# pse84 register map
Vendor: Cypress Semiconductor; Series: PSE84; File version: 1.0
CPU: CM33 r0p1, little endian, MPU, FPU, VTOR, 3 interrupt priority bits
Registers are 32-bit, read-write, reset 0x0 unless marked. A register's access mark holds for its fields unless they carry their own. Offsets are from the block's base; [hi:lo] are bit positions; lines under a group give offsets from that group; {n}, {i} and the like mark numbered series; 'fields as' and 'values as' point back to an identical list; <NAME> marks a mode.

## SRSS (part 2 of 3) — SRSS Core Registers
Base 0x42400000
0x1394 CLK_WCO_STATUS ro — WCO Status Register
  [2] WCO_OK — Indicates that output has transitioned.
0x1400 CSV_HF group — Clock Supervisor (CSV) registers for Root clocks
  {0x0+0x10*j} CSV[{j}] (j=0..13) group — Active domain Clock Supervisor (CSV) registers
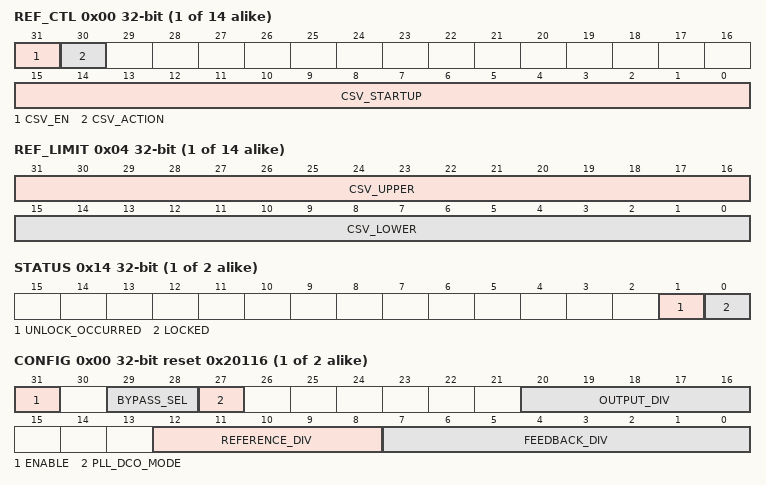
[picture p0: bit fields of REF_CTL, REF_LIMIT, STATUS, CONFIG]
    0x00 REF_CTL — Clock Supervision Reference Control
      [31] CSV_EN — Enables clock supervision, both frequency and loss. CSV in Active domain: Clock supervision is reset during DeepSleep and Hibernate modes. When enabled it begins operating automatically after a DeepSleep wakeup, but it must be reconfigured after Hibernate wakeup. CSV in DeepSleep domain: Clock supervision is reset during Hibernate mode. It must be reconfigured after Hibernate wakeup. A CSV error detection is reported to the Fault structure, or instead it can generate a power reset.
      [30] CSV_ACTION — Specifies the action taken when an anomaly is detected on the monitored clock. CSV in DeepSleep domain always do a Fault report (which also wakes up the system).
        0=FAULT (Generate a fault); 1=RESET (Cause a power reset. This should only be used for clk_hf0.)
      [15:0] CSV_STARTUP — Startup delay time -1 (in reference clock cycles), after enable or DeepSleep wakeup, from reference clock start to monitored clock start. At a minimum (both clocks running): STARTUP >= (PERIOD +3) * FREQ_RATIO - UPPER, with FREQ_RATIO = (Reference frequency / Monitored frequency) On top of that the actual clock startup delay and the margin for accuracy of both clocks must be added.
    0x04 REF_LIMIT — Clock Supervision Reference Limits
      [31:16] CSV_UPPER — Cycle time upper limit. Set the upper limit -1, in reference clock cycles, before (or same time) the next monitored clock event must happen. If a monitored clock event does not happen before this limit is reached, or does not happen at all (clock loss), a CSV error is detected.
      [15:0] CSV_LOWER — Cycle time lower limit. Set the lower limit -1, in reference clock cycles, before the next monitored clock event is allowed to happen. If a monitored clock event happens before this limit is reached a CSV error is detected. LOWER must be at least 1 less than UPPER. In case the clocks are asynchronous LOWER must be at least 3 less than UPPER.
    0x08 MON_CTL — Clock Supervision Monitor Control
      [15:0] CSV_PERIOD — Period time. Set the Period -1, in monitored clock cycles, before the next monitored clock event happens. PERIOD <= (UPPER+1) / FREQ_RATIO -1, with FREQ_RATIO = (Reference frequency / Monitored frequency) In case the clocks are asynchronous: PERIOD <= UPPER / FREQ_RATIO -1 Additionally margin must be added for accuracy of both clocks.
0x1500 CSV_REF_SEL reset 0x4 — Select CSV Reference clock for Active domain
  [2:0] REF_MUX — Selects a source for clock clk_ref_hf. Note that not all products support all clock sources. Selecting a clock source that is not supported will result in undefined behavior. It takes four cycles of the originally selected clock to switch away from it. Do not disable the original clock during this time.
    0=IMO (IMO - Internal R/C Oscillator (product specific)); 1=EXTCLK (EXTCLK - External Clock Pin); 2=ECO (ECO - External-Crystal Oscillator); 3=ALTHF0 (ALTHF0 - Alternate High-Frequency clock input (product-specific clock)); 4=IHO (IHO - Internal High-speed Oscillator); 5=ALTHF1 (ALTHF1 - Alternate High-Frequency clock input (product-specific clock))
0x1510 CSV_REF group — CSV registers for the CSV Reference clock
  0x00 CSV group — Active domain Clock Supervisor (CSV) registers for CSV Reference clock
    0x00 REF_CTL — Clock Supervision Reference Control
      fields as CSV_HF.CSV[0].REF_CTL
    0x04 REF_LIMIT — Clock Supervision Reference Limits
      fields as CSV_HF.CSV[0].REF_LIMIT
    0x08 MON_CTL — Clock Supervision Monitor Control
      fields as CSV_HF.CSV[0].MON_CTL
0x1520 CSV_LF_REF_SEL — Select CSV Reference clock for LF clock
  [1:0] LF_REF_MUX — Selects a source for clock clk_ref_lf. Note that not all products support all clock sources. Selecting a clock source that is not supported will result in undefined behavior. It takes four cycles of the originally selected clock to switch away from it. Do not disable the original clock during this time. Same clcok sources are also souce for clk_lf. Do not select the same clock.
    0=PILO (Precision internal low-speed oscillator, available in Active, DeepSleep, and Hibernate. (Product Specific)); 1=ILO (Internal Low frequency Oscillator, available in Active, DeepSleep, and Hibernate. (Product Specific)); 2=WCO (Watch-crystal oscillator input, available in Active, DeepSleep, and Hibernate. (Product Specific)); 3=TIMERCLK (Timer clock. Divided clock from IHO set to 1MHz. Available only during Active mode. If this clock is selected as reference, CSV will be disabled by hardware when entering lower power modes (DPSLP) and re-enabled back in Active.)
0x1530 CSV_LF group — CSV registers for LF clock
  0x00 CSV group — LF clock Clock Supervisor registers
    0x00 REF_CTL — Clock Supervision Reference Control
      [31] CSV_EN — Enables clock supervision, both frequency and loss. CSV in Active domain: Clock supervision is reset during DeepSleep and Hibernate modes. When enabled it begins operating automatically after a DeepSleep wakeup, but it must be reconfigured after Hibernate wakeup. CSV in DeepSleep domain: Clock supervision is reset during Hibernate mode. It must be reconfigured after Hibernate wakeup. CSV in Backup domain: Clock supervision operates during Hibernate mode, can be configured to wake from Hibernate, and continues operating during reboot. A CSV error detection is reported to the Fault structure.
      [7:0] CSV_STARTUP — Startup delay time -1 (in reference clock cycles), after enable, from reference clock start to monitored clock start. At a minimum (both clocks running): STARTUP >= (PERIOD +3) * FREQ_RATIO - UPPER, with FREQ_RATIO = (Reference frequency / Monitored frequency) On top of that the actual clock startup delay and the margin for accuracy of both clocks must be added.
    0x04 REF_LIMIT — Clock Supervision Reference Limits
      [23:16] CSV_UPPER — Cycle time upper limit. Set the upper limit -1, in reference clock cycles, before (or same time) the next monitored clock event must happen. If a monitored clock event does not happen before this limit is reached, or does not happen at all (clock loss), a CSV error is detected.
      [7:0] CSV_LOWER — Cycle time lower limit. Set the lower limit -1, in reference clock cycles, before the next monitored clock event is allowed to happen. If a monitored clock event happens before this limit is reached a CSV error is detected. LOWER must be at least 1 less than UPPER. In case the clocks are asynchronous LOWER must be at least 3 less than UPPER.
    0x08 MON_CTL — Clock Supervision Monitor Control
      [7:0] CSV_PERIOD — Period time. Set the Period -1, in monitored clock cycles, before the next monitored clock event happens. PERIOD <= (UPPER+1) / FREQ_RATIO -1, with FREQ_RATIO = (Reference frequency / Monitored frequency) In case the clocks are asynchronous: PERIOD <= UPPER / FREQ_RATIO -1 Additionally margin must be added for accuracy of both clocks.
0x1540 CSV_PILO_REF_SEL — Select CSV Reference clock for PILO clock
  [1:0] PILO_REF_MUX — Selects a source for clock clk_ref_pilo. Note that not all products support all clock sources. Selecting a clock source that is not supported will result in undefined behavior. It takes four cycles of the originally selected clock to switch away from it. Do not disable the original clock during this time. PILO is a source for clk_lf. Do not select LF when LF clock is using PILO.
    0=LFCLK (Root of the low-speed clock tree (LFCLK)); 1=ILO (Internal Low frequency Oscillator, available in Active, DeepSleep, and Hibernate. (Product Specific)); 2=WCO (Watch-crystal oscillator input, available in Active, DeepSleep, and Hibernate. (Product Specific)); 3=TIMERCLK (Timer clock. Divided clock from IHO set to 1MHz. Available only during Active mode. If this clock is selected as reference, CSV will be disabled by hardware when entering lower power modes (DPSLP) and re-enabled back in Active.)
0x1550 CSV_PILO group — CSV registers for PILO clock
  0x00 CSV group — HVILO clock DeepSleep domain Clock Supervisor registers
    0x00 REF_CTL — Clock Supervision Reference Control
      fields as CSV_LF.CSV.REF_CTL
    0x04 REF_LIMIT — Clock Supervision Reference Limits
      fields as CSV_LF.CSV.REF_LIMIT
    0x08 MON_CTL — Clock Supervision Monitor Control
      fields as CSV_LF.CSV.MON_CTL
{0x1600+0x20*i} CLK_DPLL_LP[{i}] (i=0..1) group — DPLL LP Configuration Register
  0x00 CONFIG reset 0x20116 — DPLL_LP Configuration Register
    [31] ENABLE — Master enable for PLL. Setup FEEDBACK_DIV, REFERENCE_DIV, and OUTPUT_DIV at least one cycle before setting ENABLE=1. fOUT = (FEEDBACK_DIV + FRAC_EN*FRAC_DIV/2^24) * (fREF / REFERENCE_DIV) / (OUTPUT_DIV) 0: Block is disabled. When the PLL disables, hardware controls the bypass mux as described in BYPASS_SEL, before disabling the PLL circuit. 1: Block is enabled
    [29:28] BYPASS_SEL — Bypass mux located just after PLL output. This selection is glitch-free and can be changed while the PLL is running. When changing BYPASS_SEL, do not turn off the reference clock or PLL clock for five cycles (whichever is slower).
      0=AUTO (Automatic using lock indicator. When unlocked, automatically selects PLL reference input (bypass mode). When locked, automatically selects PLL output. If ENABLE=0, automatically selects PLL reference input.); 1=LOCKED_OR_NOTHING (Similar to AUTO, except the clock is gated off when unlocked. This is compatible with clock supervision, because the supervisors allow no clock during startup (until a timeout occurs), and the clock targets the proper frequency whenever it is running. If ENABLE=0, no clock is output.); 2=PLL_BYPASS (Select PLL reference input (bypass mode). Ignores lock indicator); 3=PLL_OUT (Select PLL output. Ignores lock indicator. If ENABLE=0, no clock is output.)
    [27] PLL_DCO_MODE — dco_mode='0' DCO freq 160-310MHz , '1' - DCO freq 310-480MHz
    [20:16] OUTPUT_DIV — Control bits for Output divider. Set the divide value before enabling the PLL, and do not change it while PLL is enabled. 0: illegal (undefined behavior) 1: divide by 1. Suitable for direct usage as HFCLK source. 2: divide by 2. Suitable for direct usage as HFCLK source. ... 16: divide by 16. Suitable for direct usage as HFCLK source. >16: illegal (undefined behavior)
    [12:8] REFERENCE_DIV — Control bits for reference divider. Set the divide value before enabling the PLL, and do not change it while PLL is enabled. 0: illegal (undefined behavior) 1: divide by 1 ... 16: divide by 16 others: illegal (undefined behavior) When using fractional mode, the jitter specs are met over the restricted range of 1 to 4, inclusive.
    [7:0] FEEDBACK_DIV — Control bits for feedback divider. Set the divide value before enabling the PLL, and do not change it while PLL is enabled. 0-15: illegal (undefined behavior) 16: divide by 16 ... 200: divide by 200 >200: illegal (undefined behavior) When using fractional mode, the jitter specs are met over the restricted range of 27 to 47, inclusive.
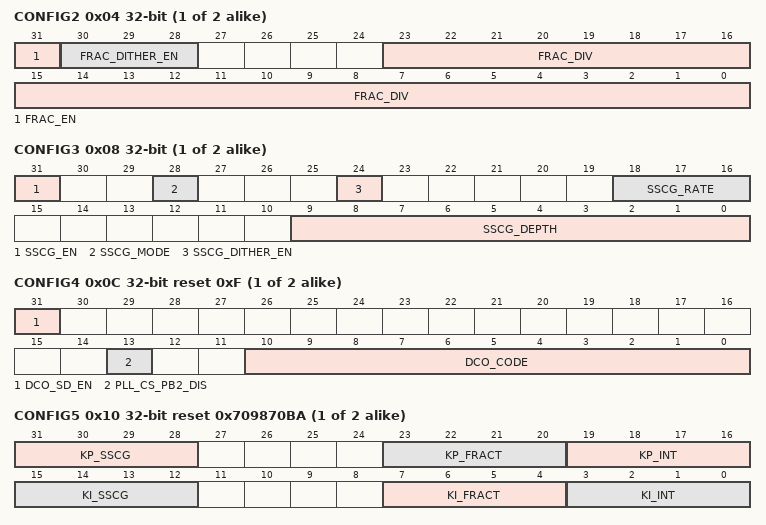
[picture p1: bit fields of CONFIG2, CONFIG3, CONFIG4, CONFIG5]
  0x04 CONFIG2 — DPLL_LP Configuration Register 2
    [31] FRAC_EN — Enables fractional division mode. When using fractional division mode, see CLK_PLL400M_CONFIG.LOCK_DELAY for an additional configuration requirement.
    [30:28] FRAC_DITHER_EN
    [23:0] FRAC_DIV — Control bits for fractional divider. This value is interpreted as a fraction of the PFD frequency, i.e. fPFD * (FRAC_DIV/2^24). This field can be dynamically updated within the 1000ppm control limit. It takes up to 115 AHB cycles to transfer the setting to the PLL, and writes that occur faster may be silently ignored and require the application to write again after the previous update has finished. Reading the register returns the accepted value. The PLL will start targeting the new value, but it may take significant time (milliseconds) to stabilize at the new average value. Do not change the FRAC_DIV setting while the PLL is initially locking.
  0x08 CONFIG3 — DPLL_LP Configuration Register 3
    [31] SSCG_EN — Enables spreading mode. When using spreading, see CLK_PLL400M_CONFIG.LOCK_DELAY for an additional configuration requirement.
    [28] SSCG_MODE
    [24] SSCG_DITHER_EN
    [18:16] SSCG_RATE
    [9:0] SSCG_DEPTH
  0x0C CONFIG4 reset 0xF — DPLL_LP Configuration Register 4
    [31] DCO_SD_EN — Enable the DCO sigma-delta modulator to reduce sideband frequency spurs caused by periodicity of DCO_CODE LSB changes. Note that enabling this introduces additional jitter which may exceed the timing closure limits near the maximum frequency. 0: disable sigma-delta modulator. 1: enable sigma-delta modulator. User must ensure the frequency remains with timing closure (consult Cypress).
    [13] PLL_CS_PB2_DIS — disable internal bias
    [10:0] DCO_CODE — Initial DCO code. It is recommended to leave this at the default setting.
  0x10 CONFIG5 reset 0x709870BA — DPLL_LP Configuration Register 5
    [31:28] KP_SSCG — Gain of P/I loop filter proportional path for SSCG operation. Gain coefficient is 2^KP, eg. 0=>1, 15=>32768.
    [23:20] KP_FRACT — Gain of P/I loop filter proportional path for FRACT operation. Gain coefficient is 2^KP, eg. 0=>1, 15=>32768.
    [19:16] KP_INT — Gain of P/I loop filter integrator path for INT operation. Gain coefficient is 2^KP, eg. 0=>1, 15=>32768.
    [15:12] KI_SSCG — Gain of P/I loop filter proportional path for SSCG operation. Gain coefficient is 2^KI, eg. 0=>1, 15=>32768.
    [7:4] KI_FRACT — Gain of P/I loop filter proportional path for FRACT operation. Gain coefficient is 2^KI, eg. 0=>1, 15=>32768.
    [3:0] KI_INT — Gain of P/I loop filter integrator path for INT operation. Gain coefficient is 2^KI, eg. 0=>1, 15=>32768.
  0x14 STATUS — DPLL_LP Status Register
    [1] UNLOCK_OCCURRED — This bit sets whenever the PLL Lock bit goes low, and stays set until cleared by firmware.
    [0] LOCKED ro — PLL Lock Indicator
0x1800 CLK_DPLL_HP group — DPLL HP Configuration Register
  0x00 CONFIG reset 0x1013 — DPLL_HP Configuration Register
    [31] ENABLE — Master enable for PLL. Setup PLL for integer, fract or SCSG at least one cycle before setting ENABLE=1. 0: Block is disabled. When the PLL disables, hardware controls the bypass mux as described in BYPASS_SEL, before disabling the PLL circuit. 1: Block is enabled
    [29:28] BYPASS_SEL — Bypass mux located just after PLL output. This selection is glitch-free and can be changed while the PLL is running. When changing BYPASS_SEL, do not turn off the reference clock or PLL clock for five cycles (whichever is slower).
      values as CLK_DPLL_LP[0].CONFIG.BYPASS_SEL
    [14:12] PLL_FREQ_KDIV_SEL — K-divider division factor (K = kdiv_sel_i + 1 )
    [10:8] PLL_FREQ_PDIV_SEL — P-divider division factor (P = pdiv_sel_i + 1 ) (Cannot be changed on the fly when the PLL is enabled)
    [7:0] PLL_FREQ_NDIV_INT_SEL — N-divider division factor (N = ndiv_sel_i + 1 ) (Cannot be changed on the fly when the PLL is enabled)
  0x04 CONFIG2 reset 0x8E00000 — DPLL_HP Configuration Register 2
    [27:24] PLL_IVR_TRIM — control word for trimming the regulated voltage that is internally generated from the 1v8 supply (default value = '10') (Cannot be changed on the fly when the PLL is enabled)
    [23:21] PLL_FREQ_MODE_SEL — selects the waiting time for Power Initialization sequence, based on the PLL running frequency (Cannot be changed on the fly when the PLL is enabled)
    [20:0] PLL_FREQ_NDIV_FRACT_SEL — N-divider division factor (N = ndiv_sel_i + 1) (Cannot be changed on the fly when the PLL is enabled)
  0x08 CONFIG3 reset 0x1 — DPLL_HP Configuration Register 3
    [29] PLL_FDSM_SEL — DSM clock division select (Cannot be changed on the fly when the PLL is enabled)
      0=DIV_BY_4 (Divide output by 4); 1=DIV_BY_2 (Divide output by 2)
    [0] PLL_CLKR_SEL — Select retimed reference clock (Cannot be changed on the fly when the PLL is enabled)
  0x0C CONFIG4 reset 0x27618AC — DPLL_HP Configuration Register 4
    [30:27] PLL_FLOCK_OBSWIN — Period over which PQDIFF is computed/observed. If 0 = use HW computed window. Supported values: 0-4 and 8 (Cannot be changed on the fly when the PLL is enabled)
    [26:23] PLL_FLOCK_LK_WAITPER — Period over which flock_en_thresh must be met in order for Freq Locking. Supported values: 0-8 (Cannot be changed on the fly when the PLL is enabled)
    [22:20] PLL_FLOCK_LK_THRESH — PQDIFF threshold under which DLL asserts Freq LOCK (Cannot be changed on the fly when the PLL is enabled)
    [19:16] PLL_FLOCK_WAITPER — Period over which flock_en_thresh must be met in order for FINE Filtering enabling. Supported values: 0-8 (Cannot be changed on the fly when the PLL is enabled)
    [13:11] PLL_FLOCK_EN_THRESH — PQDIFF threshold under which FINE Filtering gets enabled (Cannot be changed on the fly when the PLL is enabled) CONFIG.PLL_FREQ_NDIV_INT_SEL >= 20 -> PLL_FLOCK_EN_THRESH == 0x7; CONFIG.PLL_FREQ_NDIV_INT_SEL < 20 -> PLL_FLOCK_EN_THRESH == 0x3;
    [9:5] PLL_LF_LC_BETA — Beta value of the coarse filter (Cannot be changed on the fly when the PLL is enabled)
    [4:0] PLL_LF_LC_ALPHA — Alpha value of the coarse filter (Cannot be changed on the fly when the PLL is enabled)
  0x10 CONFIG5 reset 0x1294 — DPLL_HP Configuration Register 5
    [28:16] PLL_DT_CAL_DIG ro — FW should read pll_dutycal_dig_o only when pll_dutycal_ok is high to know the status of DUTY CAL circuit.
    [12] PLL_LF_SET_PARAMS — enable for external loop filter control (alpha and beta values) (Cannot be changed on the fly when the PLL is enabled)
    [9:5] PLL_LF_BETA — External beta value (Cannot be changed on the fly when the PLL is enabled) Fref/(pdiv_sel_i+1) >= 25MHz -> PLL_LF_BETA == 0x14 Fref/(pdiv_sel_i+1) < 25MHz -> PLL_LF_BETA == 0x10
    [4:0] PLL_LF_ALPHA — External alpha value (Cannot be changed on the fly when the PLL is enabled)
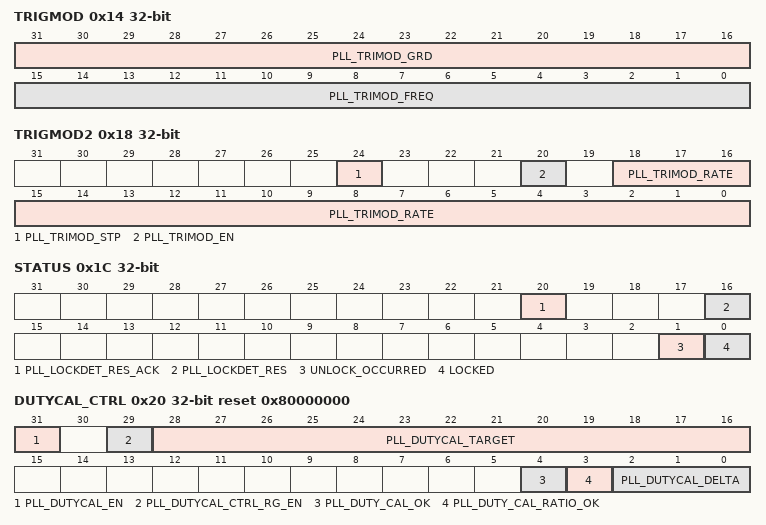
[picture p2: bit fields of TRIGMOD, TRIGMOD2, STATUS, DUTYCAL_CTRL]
  0x14 TRIGMOD — DPLL_HP Trigmod SSCG Register
    [31:16] PLL_TRIMOD_GRD — Triangular-Frequency Modulation: modulation gradient. See formula in the BROS (word file) (Can be changed when PLL is enabled but cannot be changed on the fly when pll_trimod_en_i=1)
    [15:0] PLL_TRIMOD_FREQ — Triangular-Frequency Modulation: modulation frequency. See formula in the BROS (word file) (Can be changed when PLL is enabled but cannot be changed on the fly when pll_trimod_en_i=1)
  0x18 TRIGMOD2 — DPLL_HP Trigmod2 SSCG Register
    [24] PLL_TRIMOD_STP — Triangular-Frequency Modulation stop
    [20] PLL_TRIMOD_EN — Triangular-Frequency Modulation enable
    [18:0] PLL_TRIMOD_RATE — triangular frequency modulation: trimod_rate = mod_grad_i * 16/mod_freq_i (Cannot be changed on the fly when the PLL is enabled)
  0x1C STATUS — DPLL_HP Status Register
    [20] PLL_LOCKDET_RES_ACK ro — acknowledgement for lock detection restart
    [16] PLL_LOCKDET_RES — Restart lock detector
    [1] UNLOCK_OCCURRED — This bit sets whenever the PLL Lock bit goes low, and stays set until cleared by firmware.
    [0] LOCKED ro — PLL Lock Indicator
  0x20 DUTYCAL_CTRL reset 0x80000000 — DPLL_HP_User DUTYCAL Control Register
    [31] PLL_DUTYCAL_EN — dutycal: enables duty cycle calibration (Cannot be changed on the fly when the PLL is enabled)
    [29] PLL_DUTYCAL_CTRL_RG_EN — dutycal: enables ring oscillator for duty cycle digitization (Cannot be changed on the fly when the PLL is enabled)
    [28:16] PLL_DUTYCAL_TARGET — duty cycle target (Cannot be changed on the fly when the PLL is enabled)
    [4] PLL_DUTY_CAL_OK ro — Status of the duty calibration ok
    [3] PLL_DUTY_CAL_RATIO_OK ro — Status of the duty calibration ratio ok
    [2:0] PLL_DUTYCAL_DELTA — dutycal: margins for the duty cycle calibration error (Cannot be changed on the fly when the PLL is enabled)
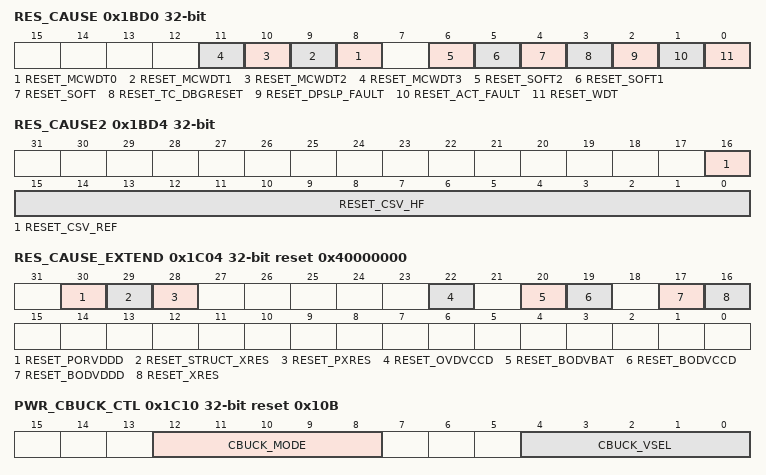
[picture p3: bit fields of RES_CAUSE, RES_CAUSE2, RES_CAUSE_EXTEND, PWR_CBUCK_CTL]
0x1BD0 RES_CAUSE — Reset Cause Observation Register
  [n+8] RESET_MCWDT{n} (n=0..3) — Multi-Counter Watchdog timer reset #{n}. This is a low-voltage cause bit that hardware clears when the low-voltage supply is initialized (see comments above).
  [6] RESET_SOFT2 — CPU[2] requested a system reset through it's SYSRESETREQ. This can be done via a debugger probe or in firmware. This is a low-voltage cause bit that hardware clears when the low-voltage supply is initialized (see comments above).
  [5] RESET_SOFT1 — CPU[1] requested a system reset through it's SYSRESETREQ. This can be done via a debugger probe or in firmware. This is a low-voltage cause bit that hardware clears when the low-voltage supply is initialized (see comments above).
  [4] RESET_SOFT — CPU[0] requested a system reset through it's SYSRESETREQ. This can be done via a debugger probe or in firmware. This is a low-voltage cause bit that hardware clears when the low-voltage supply is initialized (see comments above).
  [3] RESET_TC_DBGRESET — Test controller or debugger asserted reset. This asserts low-voltage resets including the debug domain. This is a low-voltage cause bit that hardware clears when the low-voltage supply is initialized (see comments above).
  [2] RESET_DPSLP_FAULT
  [1] RESET_ACT_FAULT — Fault logging system requested a reset from its Active logic. This is a low-voltage cause bit that hardware clears when the low-voltage supply is initialized (see comments above).
  [0] RESET_WDT — A basic WatchDog Timer (WDT) reset has occurred since last power cycle. ULP products: This is a low-voltage cause bit that hardware clears when the low-voltage supply is initialized (see comments above). For products that support high-voltage cause detection, this bit blocks recording of other high-voltage cause bits, except RESET_PORVDDD, or *XRES. Hardware clears this bit during POR. This bit is not blocked by other HV cause bits.
0x1BD4 RES_CAUSE2 — Reset Cause Observation Register 2
  [16] RESET_CSV_REF — Clock supervision logic requested a reset due to loss or frequency violation of the reference clock source that is used to monitor the other HF clock sources.
  [15:0] RESET_CSV_HF — Clock supervision logic requested a reset due to loss or frequency violation of a high-frequency clock. Each bit index K corresponds to a HFCLK<K>. Unimplemented clock bits return zero.
0x1BE4 RES_PXRES_CTL wo — Programmable XRES Control Register
  [0] PXRES_TRIGGER — Triggers PXRES. This causes a full-scope reset and reboot.
0x1C04 RES_CAUSE_EXTEND reset 0x40000000 — Extended Reset Cause Observation Register
  [30] RESET_PORVDDD — Indicator that a POR occurred. This is a high-voltage cause bit, and hardware clears the other bits when this one is set. It does not block further recording of other high-voltage causes.
  [29] RESET_STRUCT_XRES — Structural reset was asserted. This is a high-voltage cause bit that blocks recording of other high-voltage cause bits, except RESET_PORVDDD, *XRES, or WDT. Hardware clears this bit during POR. This bit is not blocked by other HV cause bits.
  [28] RESET_PXRES — PXRES triggered. This is a high-voltage cause bit that blocks recording of other high-voltage cause bits, except RESET_PORVDDD, *XRES, or WDT. Hardware clears this bit during POR. This bit is not blocked by other HV cause bits.
  [22] RESET_OVDVCCD — Overvoltage detection on the internal core VCCD supply. This is a high-voltage cause bit that blocks recording of other high-voltage cause bits, except RESET_PORVDDD, *XRES, or WDT. Hardware clears this bit during POR.
  [20] RESET_BODVBAT — External VBAT supply crossed brown-out limit. Note that this cause will only be observable as long as the VDDD supply does not go below the POR (power on reset) detection limit. Below this limit it is not possible to reliably retain information in the device. This is a high-voltage cause bit that blocks recording of other high-voltage cause bits, except RESET_PORVDDD, *XRES, or WDT. Hardware clears this bit during POR.
  [19] RESET_BODVCCD — Internal VCCD core supply crossed the brown-out limit. Note that this detector will detect gross issues with the internal core supply, but may not catch all brown-out conditions. Functional and timing supervision (CSV, WDT) is provided to create fully failsafe internal crash detection. This is a high-voltage cause bit that blocks recording of other high-voltage cause bits, except RESET_PORVDDD, *XRES, or WDT. Hardware clears this bit during POR.
  [17] RESET_BODVDDD — External VDDD supply crossed brown-out limit. Note that this cause will only be observable as long as the VDDD supply does not go below the POR (power on reset) detection limit. Below this limit it is not possible to reliably retain information in the device. This is a high-voltage cause bit that blocks recording of other high-voltage cause bits, except RESET_PORVDDD, *XRES, or WDT. Hardware clears this bit during POR.
  [16] RESET_XRES — External XRES pin was asserted. This is a high-voltage cause bit that blocks recording of other high-voltage cause bits, except RESET_PORVDDD, or WDT. Hardware clears this bit during POR. This bit is not blocked by other HV cause bits.
0x1C10 PWR_CBUCK_CTL reset 0x10B — Core Buck Control Register
  [12:8] CBUCK_MODE — CBUCK mode. Low ripple (high power) modes are intended for analog that needs low ripple. Low power mode is suitable for digital processing. The CBUCK mode is defined as = {mode*_sr_mode, mode*_sr_hp_submode[1:0], mode*_sr_lp_submode[1:0]} The actual CBUCK mode is the maximum of this setting and the settings of all enabled step-down regulators. 0x11: HP,Hysteretic PFM, High-Low (default Active) 0x01: LP,Hysteretic PFM, High-Low (default DeepSleep)
  [4:0] CBUCK_VSEL — Voltage output selection. This register is only reset by XRES, HIBERNATE wakeup, or supply supervision reset. The actual CBUCK voltage is the maximum of this setting and the settings for selected mode (see PWR_BUCK_CTL.MODE). These settings follow the formula (0.58+0.02*CBUCK_VSEL). 0: 0.58V, 1: 0.60V, 2: 0.62V, 3: 0.64V, 4: 0.66V, 5: 0.68V, 6: 0.70V, 7: 0.72V, 8: 0.74V, 9: 0.76V, 10: 0.78V, 11: 0.80V, 12: 0.82V, 13: 0.84V, 14: 0.86V, 15: 0.88V, 16: 0.90V, 17: 0.92V, 18: 0.94V, 19: 0.96V, 20: 0.98V, 21: 1.00V, 22: 1.02V, 23: 1.04V, 24: 1.06V, 25: 1.08V, 26: 1.10V, 27: 1.12V, 28: 1.14V, 29: 1.16V, 30: 1.18V, 31: 1.20V.
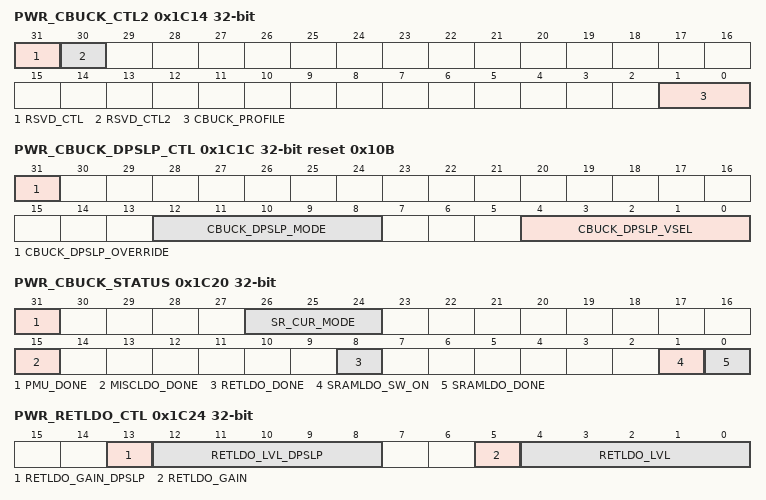
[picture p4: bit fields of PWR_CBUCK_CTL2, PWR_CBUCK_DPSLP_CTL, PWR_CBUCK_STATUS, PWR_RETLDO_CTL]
0x1C14 PWR_CBUCK_CTL2 — Core Buck Control Register 2
  [31] RSVD_CTL
  [30] RSVD_CTL2
  [1:0] CBUCK_PROFILE — Selects between CBUCK mode profiles. When CBUCK_USE_SETTING=1, PWR_CBUCK_CTL settings are included in the harmonization and the maximum of the respective mode is used. 00: Mode0: VSEL=0.8V; MODE= HP,Hysteretic PFM, High-Low (17) 01: Mode1: VSEL=0.7V; MODE=17 10: Mode2: VSEL=0.9V; MODE=17 11: Forces the CBUCK to use the settings in PWR_CBUCK_CTL register, ignoring the other hardware requests. This can be used as part of a firmware algorithm to change the voltage of an regulator. This bit is cleared by any reset].
0x1C1C PWR_CBUCK_DPSLP_CTL reset 0x10B — Core Buck Deepsleep Control Register
  [31] CBUCK_DPSLP_OVERRIDE — Causes the settings in CBUCK_DPSLP_VSEL and CBUCK_DPSLP_MODE in this register to be used during DEEPSLEEP. Can be used to override the normal hardware voltage behavior of 0.7V and LP, LP,Hysteretic PFM, High-Low (default DeepSleep)
  [12:8] CBUCK_DPSLP_MODE — CBUCK mode. Low ripple (high power) modes are intended for analog that needs low ripple. Low power mode is suitable for digital processing. The CBUCK mode is defined as = {mode*_sr_mode, mode*_sr_hp_submode[1:0], mode*_sr_lp_submode[1:0]} CBUCK_DPSLP_OVERRIDE=1 will casue these settings to be used during DEEPSLEEP mode. 0x11: HP,Hysteretic PFM, High-Low (default Active) 0x01: LP,Hysteretic PFM, High-Low (default DeepSleep)
  [4:0] CBUCK_DPSLP_VSEL — Voltage output selection for DEEPSLEEP. CBUCK_DPSLP_OVERRIDE=1 will casue these settings to be used during DEEPSLEEP mode. This register is only reset by XRES, HIBERNATE wakeup, or supply supervision reset. These settings follow the formula (0.58+0.02*CBUCK_VSEL). 0: 0.58V, 1: 0.60V, 2: 0.62V, 3: 0.64V, 4: 0.66V, 5: 0.68V, 6: 0.70V, 7: 0.72V, 8: 0.74V, 9: 0.76V, 10: 0.78V, 11: 0.80V, 12: 0.82V, 13: 0.84V, 14: 0.86V, 15: 0.88V, 16: 0.90V, 17: 0.92V, 18: 0.94V, 19: 0.96V, 20: 0.98V, 21: 1.00V, 22: 1.02V, 23: 1.04V, 24: 1.06V, 25: 1.08V, 26: 1.10V, 27: 1.12V, 28: 1.14V, 29: 1.16V, 30: 1.18V, 31: 1.20V.
0x1C20 PWR_CBUCK_STATUS ro — Core Buck Status Register
  [31] PMU_DONE — Indicates the power management unit is finished with a transition. 0: PMU busy 1: PMU done
  [26:24] SR_CUR_MODE — Indicates the switching regulator current operating mode
  [15] MISCLDO_DONE — Indicates the MISCLDO is finished with a transition. 0: MISCLDO busy 1: MISCLDO done
  [8] RETLDO_DONE — Indicates the RETLDO is finished with a transition. 0: RETLDO busy 1: RETLDO done
  [1] SRAMLDO_SW_ON — Indicates the state of the SRAMLDO bypass switch 0: SRAMLDO enabled 1: SRAMLDO bypassed
  [0] SRAMLDO_DONE — Indicates the SRAMLDO is finished with a transition. 0: SRAMLDO busy 1: SRAMLDO done
0x1C24 PWR_RETLDO_CTL — RETLDO Control Register
  [13] RETLDO_GAIN_DPSLP — RETLDO Gain during Deepslp modes 0: 2.00 1: 2.47
  [12:8] RETLDO_LVL_DPSLP — RETLDO output voltage during DEEPSLEEP modes retldo_gain=0 retldo_gain=1 retref_lvl Temp Temp 25C-125C Temp Temp 25C-125C <4:0> -40C -40C 00000 0.6150 0.550 0.7595 0.679 00001 0.6262 0.560 0.7733 0.691 00010 0.6374 0.570 0.7871 0.704 00011 0.6485 0.580 0.8010 0.716 00100 0.6597 0.590 0.8148 0.728 00101 0.6709 0.600 0.8286 0.741 00110 0.6821 0.610 0.8424 0.753 00111 0.6933 0.620 0.8562 0.765 01000 0.7045 0.630 0.8700 0.778 01001 0.7045 0.630 0.8700 0.778 01010 0.7045 0.630 0.8700 0.778 01011 0.7045 0.630 0.8700 0.778 01100 0.7045 0.630 0.8700 0.778 01101 0.7045 0.630 0.8700 0.778 01110 0.7045 0.630 0.8700 0.778 01111 0.7045 0.630 0.8700 0.778 10000 0.4361 0.390 0.5386 0.481 10001 0.4473 0.400 0.5524 0.494 10010 0.4585 0.410 0.5662 0.506 10011 0.4696 0.420 0.5800 0.519 10100 0.4808 0.430 0.5938 0.531 10101 0.4920 0.440 0.6076 0.543 10110 0.5032 0.450 0.6214 0.556 10111 0.5144 0.460 0.6352 0.568 11000 0.5255 0.470 0.6490 0.580 11001 0.5367 0.480 0.6629 0.593 11010 0.5479 0.490 0.6767 0.605 11011 0.5591 0.500 0.6905 0.617 11100 0.5703 0.510 0.7043 0.630 11101 0.5815 0.520 0.7181 0.642 11110 0.5926 0.530 0.7319 0.654 11111 0.6038 0.540 0.7457 0.667
  [5] RETLDO_GAIN — RETLDO Gain During Active mode 0: 2.00 1: 2.47
  [4:0] RETLDO_LVL — RETLDO output voltage during DEEPSLEEP modes retldo_gain=0 retldo_gain=1 retref_lvl Temp Temp 25C-125C Temp Temp 25C-125C <4:0> -40C -40C 00000 0.6150 0.550 0.7595 0.679 00001 0.6262 0.560 0.7733 0.691 00010 0.6374 0.570 0.7871 0.704 00011 0.6485 0.580 0.8010 0.716 00100 0.6597 0.590 0.8148 0.728 00101 0.6709 0.600 0.8286 0.741 00110 0.6821 0.610 0.8424 0.753 00111 0.6933 0.620 0.8562 0.765 01000 0.7045 0.630 0.8700 0.778 01001 0.7045 0.630 0.8700 0.778 01010 0.7045 0.630 0.8700 0.778 01011 0.7045 0.630 0.8700 0.778 01100 0.7045 0.630 0.8700 0.778 01101 0.7045 0.630 0.8700 0.778 01110 0.7045 0.630 0.8700 0.778 01111 0.7045 0.630 0.8700 0.778 10000 0.4361 0.390 0.5386 0.481 10001 0.4473 0.400 0.5524 0.494 10010 0.4585 0.410 0.5662 0.506 10011 0.4696 0.420 0.5800 0.519 10100 0.4808 0.430 0.5938 0.531 10101 0.4920 0.440 0.6076 0.543 10110 0.5032 0.450 0.6214 0.556 10111 0.5144 0.460 0.6352 0.568 11000 0.5255 0.470 0.6490 0.580 11001 0.5367 0.480 0.6629 0.593 11010 0.5479 0.490 0.6767 0.605 11011 0.5591 0.500 0.6905 0.617 11100 0.5703 0.510 0.7043 0.630 11101 0.5815 0.520 0.7181 0.642 11110 0.5926 0.530 0.7319 0.654 11111 0.6038 0.540 0.7457 0.667
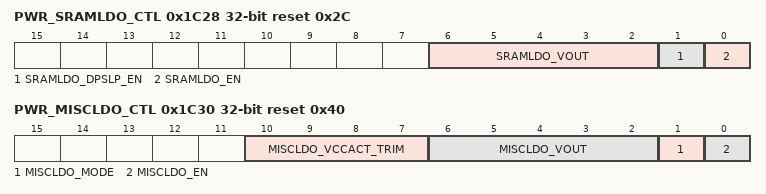
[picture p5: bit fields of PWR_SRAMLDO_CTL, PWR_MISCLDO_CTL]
0x1C28 PWR_SRAMLDO_CTL reset 0x2C — SRAMLDO Control Register
  [6:2] SRAMLDO_VOUT — SRAMLDO output voltage Setting Voltage(V) Setting Voltage(V) 00000 0.58 10000 0.90 00001 0.60 10001 0.92 00001 0.60 10001 0.92 00010 0.62 10010 0.94 00011 0.64 10011 0.96 00100 0.66 10100 0.98 00101 0.68 10101 1.00 00110 0.70 10110 1.02 00111 0.72 10111 1.04 01000 0.74 11000 1.06 01001 0.76 11001 1.08 01010 0.78 11010 1.10 01011 0.80 11011 1.12 01100 0.82 11100 1.14 01101 0.84 11101 1.16 01110 0.86 11110 1.18 01111 0.88 11111 1.20
  [1] SRAMLDO_DPSLP_EN — Enable SRAMLDO during deepsleep modes for fast wakeup time versus power savings.
  [0] SRAMLDO_EN — SRAM LDO enable 0: Disabled (switch VCCD->VCCSRAM enabled) 1: Enabled (switch VCCD->VCCSRAM disabled)
0x1C30 PWR_MISCLDO_CTL reset 0x40 — MISCLDO Control Register
  [10:7] MISCLDO_VCCACT_TRIM — MISCLDO VCCACT_MISC trim adjustment. Proportional to VCCACT_MISC, numbers below at 0.9V. Setting Adj @0.9V 0111 35mV 0110 30mV 0101 25mV 0100 20mV 0011 15mV 0010 10mV 0001 5mV 0000 0mV 1111 -5mV 1110 -10mV 1110 -10mV 1101 -15mV 1100 -20mV 1011 -25mV 1010 -30mV 1001 -35mV 1000 -40mV
  [6:2] MISCLDO_VOUT — MISCLDO output voltage Setting Voltage(V) Setting Voltage(V) 00000 0.58 10000 0.90 00001 0.60 10001 0.92 00010 0.62 10010 0.94 00011 0.64 10011 0.96 00100 0.66 10100 0.98 00101 0.68 10101 1.00 00110 0.70 10110 1.02 00111 0.72 10111 1.04 01000 0.74 11000 1.06 01001 0.76 11001 1.08 01010 0.78 11010 1.10 01011 0.80 11011 1.12 01100 0.82 11100 1.14 01101 0.84 11101 1.16 01110 0.86 11110 1.18 01111 0.88 11111 1.20
  [1] MISCLDO_MODE — MISCLDO voltage mode 0: MISCLDO output follows VCCACT_MISC 1: MISCLDO output follows miscldo_vout<4:0>
  [0] MISCLDO_EN — MISCLDO enable
